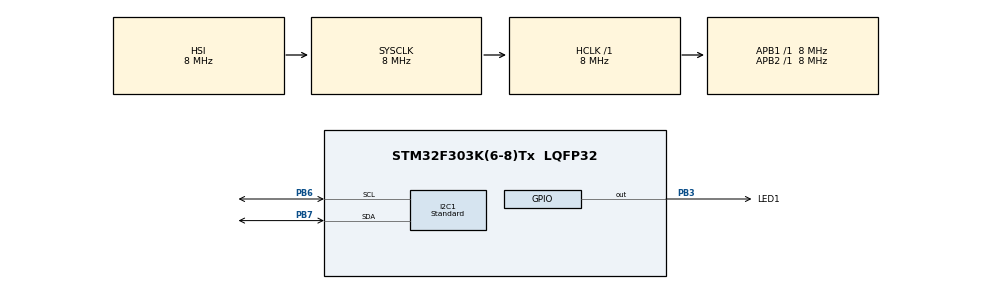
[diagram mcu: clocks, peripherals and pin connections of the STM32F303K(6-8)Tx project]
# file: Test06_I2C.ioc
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Dma.I2C1_RX.0.Direction=DMA_PERIPH_TO_MEMORY
Dma.I2C1_RX.0.Instance=DMA1_Channel3
Dma.I2C1_RX.0.MemDataAlignment=DMA_MDATAALIGN_BYTE
Dma.I2C1_RX.0.MemInc=DMA_MINC_ENABLE
Dma.I2C1_RX.0.Mode=DMA_CIRCULAR
Dma.I2C1_RX.0.PeriphDataAlignment=DMA_PDATAALIGN_BYTE
Dma.I2C1_RX.0.PeriphInc=DMA_PINC_DISABLE
Dma.I2C1_RX.0.Priority=DMA_PRIORITY_LOW
Dma.Request0=I2C1_RX
I2C1.I2C_Speed_Mode=I2C_Standard
I2C1.Timing=0x2000090E
Mcu.Family=STM32F3
Mcu.Name=STM32F303K(6-8)Tx
Mcu.Package=LQFP32
NVIC.DMA1_Channel3_IRQn=true\:0\:0\:false\:false\:true
NVIC.PriorityGroup=NVIC_PRIORITYGROUP_4
PB3.GPIO_Label=LED1
PB3.Signal=GPIO_Output
PB6.Mode=I2C
PB6.Signal=I2C1_SCL
PB7.Mode=I2C
PB7.Signal=I2C1_SDA
ProjectManager.HeapSize=0x200
ProjectManager.StackSize=0x400
ProjectManager.TargetToolchain=SW4STM32
RCC.AHBFreq_Value=8000000
RCC.APB1Freq_Value=8000000
RCC.APB2Freq_Value=8000000
RCC.CortexFreq_Value=8000000
RCC.HSE_VALUE=8000000
RCC.HSI_VALUE=8000000
RCC.SYSCLKFreq_VALUE=8000000
board=Test06_I2C

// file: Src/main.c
/**
  ******************************************************************************
  * File Name          : main.c
  * Description        : Main program body
  ******************************************************************************
  *
  * COPYRIGHT(c) 2017 STMicroelectronics
  *
  * Redistribution and use in source and binary forms, with or without modification,
  * are permitted provided that the following conditions are met:
  *   1. Redistributions of source code must retain the above copyright notice,
  *      this list of conditions and the following disclaimer.
  *   2. Redistributions in binary form must reproduce the above copyright notice,
  *      this list of conditions and the following disclaimer in the documentation
  *      and/or other materials provided with the distribution.
  *   3. Neither the name of STMicroelectronics nor the names of its contributors
  *      may be used to endorse or promote products derived from this software
  *      without specific prior written permission.
  *
  * THIS SOFTWARE IS PROVIDED BY THE COPYRIGHT HOLDERS AND CONTRIBUTORS "AS IS"
  * AND ANY EXPRESS OR IMPLIED WARRANTIES, INCLUDING, BUT NOT LIMITED TO, THE
  * IMPLIED WARRANTIES OF MERCHANTABILITY AND FITNESS FOR A PARTICULAR PURPOSE ARE
  * DISCLAIMED. IN NO EVENT SHALL THE COPYRIGHT HOLDER OR CONTRIBUTORS BE LIABLE
  * FOR ANY DIRECT, INDIRECT, INCIDENTAL, SPECIAL, EXEMPLARY, OR CONSEQUENTIAL
  * DAMAGES (INCLUDING, BUT NOT LIMITED TO, PROCUREMENT OF SUBSTITUTE GOODS OR
  * SERVICES; LOSS OF USE, DATA, OR PROFITS; OR BUSINESS INTERRUPTION) HOWEVER
  * CAUSED AND ON ANY THEORY OF LIABILITY, WHETHER IN CONTRACT, STRICT LIABILITY,
  * OR TORT (INCLUDING NEGLIGENCE OR OTHERWISE) ARISING IN ANY WAY OUT OF THE USE
  * OF THIS SOFTWARE, EVEN IF ADVISED OF THE POSSIBILITY OF SUCH DAMAGE.
  *
  ******************************************************************************
  */
#include "main.h"
#include "stm32f3xx_hal.h"

I2C_HandleTypeDef hi2c1;
DMA_HandleTypeDef hdma_i2c1_rx;

/* USER CODE BEGIN PV */
/* Private variables ---------------------------------------------------------*/

/* USER CODE END PV */

void SystemClock_Config(void);
void Error_Handler(void);
static void MX_GPIO_Init(void);
static void MX_DMA_Init(void);
static void MX_I2C1_Init(void);

/* USER CODE BEGIN PFP */
/* Private function prototypes -----------------------------------------------*/

/* USER CODE END PFP */

int main(void)
{

  /* USER CODE BEGIN 1 */
	uint8_t read=0;
	uint8_t address=0x75;//WHO_AM_I
	uint8_t config=0x12;
	uint8_t set[]={0x1A,0x12};
	uint8_t dat=0x00;
  /* USER CODE END 1 */

  /* MCU Configuration----------------------------------------------------------*/

  /* Reset of all peripherals, Initializes the Flash interface and the Systick. */
  HAL_Init();

  /* Configure the system clock */
  SystemClock_Config();

  /* Initialize all configured peripherals */
  MX_GPIO_Init();
  MX_DMA_Init();
  MX_I2C1_Init();

  /* Infinite loop */
  while (1)
  {

  /* USER CODE BEGIN 3 */
//READ MPU6050(0xD0) WHO_AM_I(0x75)
		HAL_I2C_Mem_Read(&hi2c1,0xD0/*device ID*/,0x75/*WHO_AM_I*/,I2C_MEMADD_SIZE_8BIT/*Memory Address Size*/,&read/*Data Buffer*/,1,10);
		if( read == 0x68 ){
//			HAL_GPIO_WritePin(LED1_GPIO_Port,LED1_Pin,GPIO_PIN_SET);
//if 'read' have correct data
			while(1){
//if(
				//wakeup sensor
				HAL_I2C_Mem_Write(&hi2c1,0xD0,0x6B,I2C_MEMADD_SIZE_8BIT,&dat,1,10);
				HAL_I2C_Mem_Read(&hi2c1,0xD0,0x6B,I2C_MEMADD_SIZE_8BIT,&read,1,10);
				//configure sensor
				HAL_I2C_Mem_Write(&hi2c1,0xD0,0x1a,I2C_MEMADD_SIZE_8BIT,&config,1,10);
				HAL_I2C_Mem_Read(&hi2c1,0xD0,0x1a,I2C_MEMADD_SIZE_8BIT,&read,1,10);
				if(read==0x12){
		//if 'read' have correct data
					HAL_GPIO_WritePin(LED1_GPIO_Port,LED1_Pin,GPIO_PIN_SET);
				}else{/*read == 0x12*/
		//if 'read' have wrong data
					while(1){
						HAL_GPIO_WritePin(LED1_GPIO_Port,LED1_Pin,GPIO_PIN_SET);
						HAL_Delay(50);
						HAL_GPIO_WritePin(LED1_GPIO_Port,LED1_Pin,GPIO_PIN_RESET);
						HAL_Delay(200);
					}
				}
			}

		}else{/*read == 0x68*/
//if 'read' have wrong data
			while(1){
				HAL_GPIO_WritePin(LED1_GPIO_Port,LED1_Pin,GPIO_PIN_SET);
				HAL_Delay(200);
				HAL_GPIO_WritePin(LED1_GPIO_Port,LED1_Pin,GPIO_PIN_RESET);
				HAL_Delay(50);
			}
		}
  }
  /* USER CODE END 3 */

}

/** System Clock Configuration
*/
void SystemClock_Config(void)
{

  RCC_OscInitTypeDef RCC_OscInitStruct;
  RCC_ClkInitTypeDef RCC_ClkInitStruct;
  RCC_PeriphCLKInitTypeDef PeriphClkInit;

    /**Initializes the CPU, AHB and APB busses clocks
    */
  RCC_OscInitStruct.OscillatorType = RCC_OSCILLATORTYPE_HSI;
  RCC_OscInitStruct.HSIState = RCC_HSI_ON;
  RCC_OscInitStruct.HSICalibrationValue = 16;
  RCC_OscInitStruct.PLL.PLLState = RCC_PLL_NONE;
  if (HAL_RCC_OscConfig(&RCC_OscInitStruct) != HAL_OK)
  {
    Error_Handler();
  }

    /**Initializes the CPU, AHB and APB busses clocks
    */
  RCC_ClkInitStruct.ClockType = RCC_CLOCKTYPE_HCLK|RCC_CLOCKTYPE_SYSCLK
                              |RCC_CLOCKTYPE_PCLK1|RCC_CLOCKTYPE_PCLK2;
  RCC_ClkInitStruct.SYSCLKSource = RCC_SYSCLKSOURCE_HSI;
  RCC_ClkInitStruct.AHBCLKDivider = RCC_SYSCLK_DIV1;
  RCC_ClkInitStruct.APB1CLKDivider = RCC_HCLK_DIV1;
  RCC_ClkInitStruct.APB2CLKDivider = RCC_HCLK_DIV1;

  if (HAL_RCC_ClockConfig(&RCC_ClkInitStruct, FLASH_LATENCY_0) != HAL_OK)
  {
    Error_Handler();
  }

  PeriphClkInit.PeriphClockSelection = RCC_PERIPHCLK_I2C1;
  PeriphClkInit.I2c1ClockSelection = RCC_I2C1CLKSOURCE_HSI;
  if (HAL_RCCEx_PeriphCLKConfig(&PeriphClkInit) != HAL_OK)
  {
    Error_Handler();
  }

    /**Configure the Systick interrupt time
    */
  HAL_SYSTICK_Config(HAL_RCC_GetHCLKFreq()/1000);

    /**Configure the Systick
    */
  HAL_SYSTICK_CLKSourceConfig(SYSTICK_CLKSOURCE_HCLK);

  /* SysTick_IRQn interrupt configuration */
  HAL_NVIC_SetPriority(SysTick_IRQn, 0, 0);
}

/* I2C1 init function */
static void MX_I2C1_Init(void)
{

  hi2c1.Instance = I2C1;
  hi2c1.Init.Timing = 0x2000090E;
  hi2c1.Init.OwnAddress1 = 0;
  hi2c1.Init.AddressingMode = I2C_ADDRESSINGMODE_7BIT;
  hi2c1.Init.DualAddressMode = I2C_DUALADDRESS_DISABLE;
  hi2c1.Init.OwnAddress2 = 0;
  hi2c1.Init.OwnAddress2Masks = I2C_OA2_NOMASK;
  hi2c1.Init.GeneralCallMode = I2C_GENERALCALL_DISABLE;
  hi2c1.Init.NoStretchMode = I2C_NOSTRETCH_DISABLE;
  if (HAL_I2C_Init(&hi2c1) != HAL_OK)
  {
    Error_Handler();
  }

    /**Configure Analogue filter
    */
  if (HAL_I2CEx_ConfigAnalogFilter(&hi2c1, I2C_ANALOGFILTER_ENABLE) != HAL_OK)
  {
    Error_Handler();
  }

}

static void MX_DMA_Init(void)
{
  /* DMA controller clock enable */
  __HAL_RCC_DMA1_CLK_ENABLE();

  /* DMA interrupt init */
  /* DMA1_Channel3_IRQn interrupt configuration */
  HAL_NVIC_SetPriority(DMA1_Channel3_IRQn, 0, 0);
  HAL_NVIC_EnableIRQ(DMA1_Channel3_IRQn);

}

/** Configure pins as
        * Analog
        * Input
        * Output
        * EVENT_OUT
        * EXTI
*/
static void MX_GPIO_Init(void)
{

  GPIO_InitTypeDef GPIO_InitStruct;

  /* GPIO Ports Clock Enable */
  __HAL_RCC_GPIOB_CLK_ENABLE();

  /*Configure GPIO pin Output Level */
  HAL_GPIO_WritePin(LED1_GPIO_Port, LED1_Pin, GPIO_PIN_RESET);

  /*Configure GPIO pin : LED1_Pin */
  GPIO_InitStruct.Pin = LED1_Pin;
  GPIO_InitStruct.Mode = GPIO_MODE_OUTPUT_PP;
  GPIO_InitStruct.Pull = GPIO_NOPULL;
  GPIO_InitStruct.Speed = GPIO_SPEED_FREQ_LOW;
  HAL_GPIO_Init(LED1_GPIO_Port, &GPIO_InitStruct);

}

void Error_Handler(void)
{
  /* USER CODE BEGIN Error_Handler */
  /* User can add his own implementation to report the HAL error return state */
  while(1)
  {
		HAL_GPIO_WritePin(LED1_GPIO_Port,LED1_Pin,GPIO_PIN_SET);
		HAL_Delay(50);
		HAL_GPIO_WritePin(LED1_GPIO_Port,LED1_Pin,GPIO_PIN_RESET);
		HAL_Delay(50);
  }
  /* USER CODE END Error_Handler */
}

/************************ (C) COPYRIGHT STMicroelectronics *****END OF FILE****/
